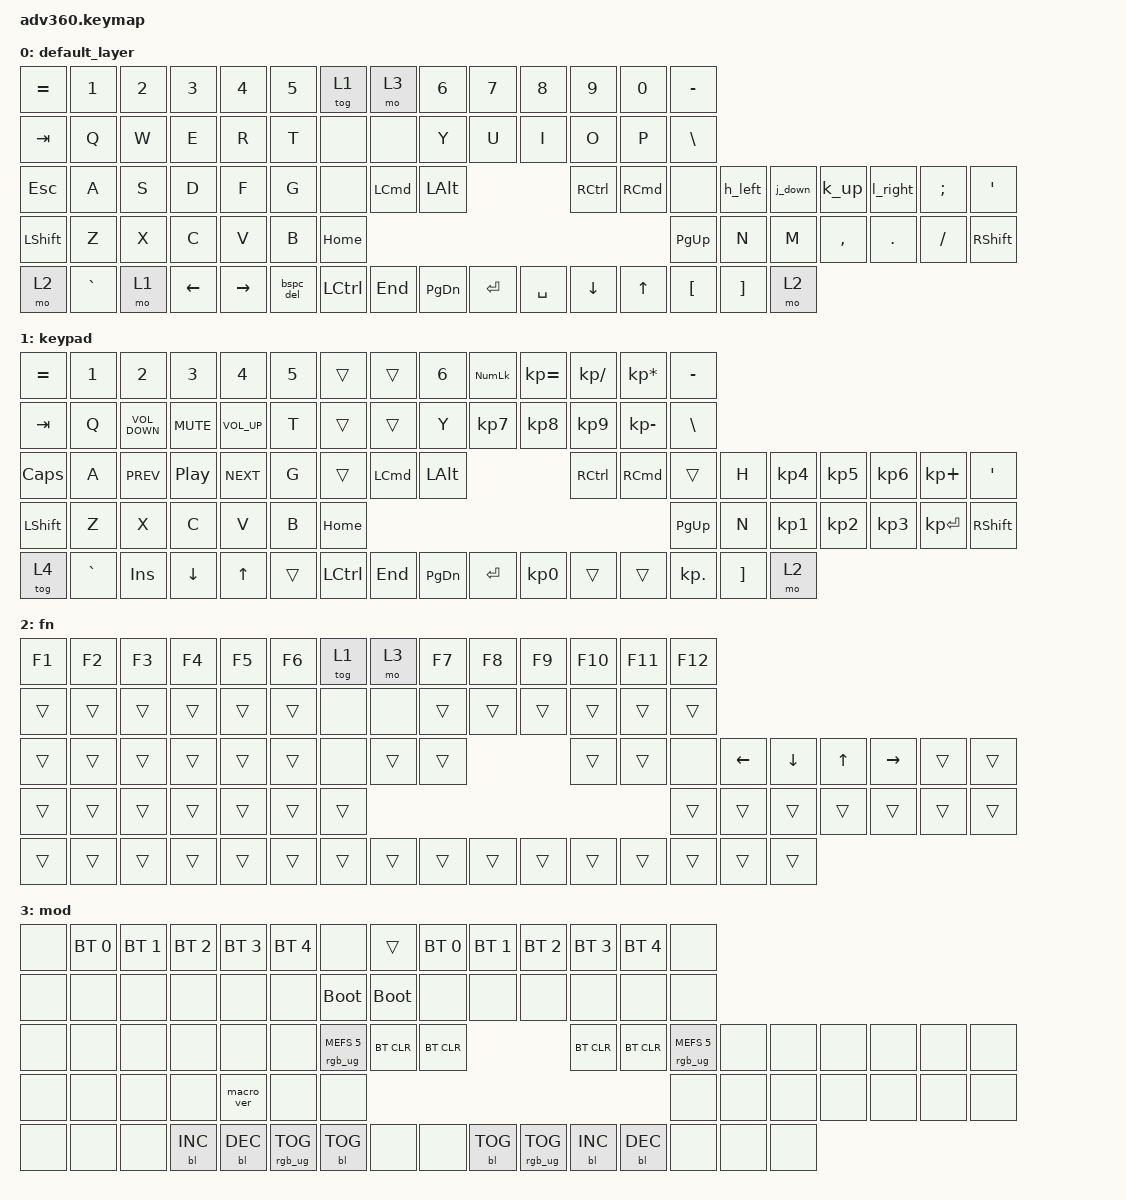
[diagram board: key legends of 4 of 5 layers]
#include <behaviors.dtsi>
#include <dt-bindings/zmk/keys.h>
#include <dt-bindings/zmk/bt.h>
#include <dt-bindings/zmk/rgb.h>
#include <dt-bindings/zmk/backlight.h>

&mt {
    tapping-term-ms = <200>;
};

/ {
    behaviors {
        #include "macros.dtsi"
        #include "version.dtsi"
        #ifndef VERSION_MACRO
        macro_ver: macro_ver {
          compatible = "zmk,behavior-macro";
          label = "macro_version";
          #binding-cells = <0>;
          bindings = <&kp RET>;
        };
        #endif

        hm: homerow_mods {
            compatible = "zmk,behavior-hold-tap";
            label = "HOMEROW_MODS";
            #binding-cells = <2>;
            tapping-term-ms = <200>;
            quick_tap_ms = <175>;
            flavor = "tap-preferred";
            bindings =
                <&kp>,
                <&kp>;
        };

        bspc_del: backspace_delete {
            compatible = "zmk,behavior-mod-morph";
            label = "SHIFT_DELETE";
            #binding-cells = <0>;
            bindings = <&kp BACKSPACE>, <&kp DELETE>;
            mods = <(MOD_LSFT|MOD_RSFT)>;
            keep-mods = <(MOD_RSFT)>;
        };

        k_up: k_up {
            compatible = "zmk,behavior-mod-morph";
            label = "K_UP";
            #binding-cells = <0>;
            bindings = <&kp K>, <&kp UP>;
            mods = <(MOD_RCTL)>;
        };

        j_down: j_down {
            compatible = "zmk,behavior-mod-morph";
            label = "J_DOWN";
            #binding-cells = <0>;
            bindings = <&kp J>, <&kp DOWN>;
            mods = <(MOD_RCTL)>;
        };

        h_left: h_left {
            compatible = "zmk,behavior-mod-morph";
            label = "H_LEFT";
            #binding-cells = <0>;
            bindings = <&kp H>, <&kp LEFT>;
            mods = <(MOD_RCTL)>;
        };

        l_right: l_right {
            compatible = "zmk,behavior-mod-morph";
            label = "L_RIGHT";
            #binding-cells = <0>;
            bindings = <&kp L>, <&kp RIGHT>;
            mods = <(MOD_RCTL)>;
        };
    };

    keymap {
        compatible = "zmk,keymap";

        default_layer {
            bindings = <
                &kp EQUAL     &kp N1  &kp N2    &kp N3     &kp N4         &kp N5            &tog 1             &mo 3     &kp N6     &kp N7     &kp N8             &kp N9             &kp N0  &kp MINUS
                  &kp TAB      &kp Q   &kp W     &kp E      &kp R          &kp T             &none             &none      &kp Y      &kp U      &kp I              &kp O              &kp P   &kp BSLH
                  &kp ESC      &kp A   &kp S     &kp D      &kp F          &kp G             &none  &kp LEFT_COMMAND   &kp LALT                        &kp RIGHT_CONTROL  &kp RIGHT_COMMAND      &none   &h_left &j_down      &k_up &l_right  &kp SEMI    &kp SQT
                &kp LSHFT      &kp Z   &kp X     &kp C      &kp V          &kp B                                       &kp HOME                                &kp PG_UP                                   &kp N   &kp M  &kp COMMA  &kp DOT  &kp FSLH  &kp RSHFT
                    &mo 2  &kp GRAVE   &mo 1  &kp LEFT  &kp RIGHT      &bspc_del  &kp LEFT_CONTROL           &kp END  &kp PG_DN  &kp ENTER  &kp SPACE           &kp DOWN             &kp UP   &kp LBKT  &kp RBKT   &mo 2
            >;
        };

        keypad {
            bindings = <
                   &kp EQUAL     &kp N1             &kp N2      &kp N3           &kp N4      &kp N5            &trans            &trans     &kp N6  &kp KP_NUM  &kp KP_EQUAL      &kp KP_DIVIDE    &kp KP_MULTIPLY   &kp MINUS
                     &kp TAB      &kp Q  &kp C_VOLUME_DOWN  &kp C_MUTE  &kp C_VOLUME_UP       &kp T            &trans            &trans      &kp Y   &kp KP_N7     &kp KP_N8          &kp KP_N9       &kp KP_MINUS    &kp BSLH
                &kp CAPSLOCK      &kp A         &kp C_PREV    &kp C_PP       &kp C_NEXT       &kp G            &trans  &kp LEFT_COMMAND   &kp LALT                            &kp RIGHT_CONTROL  &kp RIGHT_COMMAND      &trans     &kp H  &kp KP_N4  &kp KP_N5  &kp KP_N6   &kp KP_PLUS    &kp SQT
                   &kp LSHFT      &kp Z              &kp X       &kp C            &kp V       &kp B                                       &kp HOME                                    &kp PG_UP                                    &kp N  &kp KP_N1  &kp KP_N2  &kp KP_N3  &kp KP_ENTER  &kp RSHFT
                      &tog 4  &kp GRAVE         &kp INSERT    &kp DOWN           &kp UP      &trans  &kp LEFT_CONTROL           &kp END  &kp PG_DN   &kp ENTER     &kp KP_N0             &trans             &trans  &kp KP_DOT  &kp RBKT      &mo 2
            >;
        };

        fn {
            bindings = <
                &kp F1  &kp F2  &kp F3  &kp F4  &kp F5  &kp F6  &tog 1   &mo 3  &kp F7  &kp F8  &kp F9  &kp F10  &kp F11  &kp F12
                &trans  &trans  &trans  &trans  &trans  &trans   &none   &none  &trans  &trans  &trans   &trans   &trans   &trans
                &trans  &trans  &trans  &trans  &trans  &trans   &none  &trans  &trans                   &trans   &trans    &none  &kp LEFT  &kp DOWN  &kp UP  &kp RIGHT  &trans  &trans
                &trans  &trans  &trans  &trans  &trans  &trans                  &trans                   &trans                      &trans    &trans  &trans     &trans  &trans  &trans
                &trans  &trans  &trans  &trans  &trans  &trans  &trans  &trans  &trans  &trans  &trans   &trans   &trans   &trans    &trans    &trans
            >;
        };

        mod {
            bindings = <
                &none  &bt BT_SEL 0  &bt BT_SEL 1  &bt BT_SEL 2  &bt BT_SEL 3     &bt BT_SEL 4                   &none       &trans  &bt BT_SEL 0  &bt BT_SEL 1     &bt BT_SEL 2  &bt BT_SEL 3  &bt BT_SEL 4                   &none
                &none         &none         &none         &none         &none            &none             &bootloader  &bootloader         &none         &none            &none         &none         &none                   &none
                &none         &none         &none         &none         &none            &none  &rgb_ug RGB_MEFS_CMD 5   &bt BT_CLR    &bt BT_CLR                                   &bt BT_CLR    &bt BT_CLR  &rgb_ug RGB_MEFS_CMD 5   &none   &none   &none   &none   &none   &none
                &none         &none         &none         &none         &macro_ver       &none                                              &none                                        &none                                         &none   &none   &none   &none   &none   &none
                &none         &none         &none    &bl BL_INC    &bl BL_DEC  &rgb_ug RGB_TOG              &bl BL_TOG        &none         &none    &bl BL_TOG  &rgb_ug RGB_TOG    &bl BL_INC    &bl BL_DEC                   &none   &none   &none
            >;
        };

        gaming {
            bindings = <
                &trans      &trans   &trans     &trans      &trans             &trans     &trans             &trans      &trans                        &trans      &trans              &trans              &trans     &trans
                &trans      &trans   &trans     &trans      &trans             &trans     &trans             &trans      &trans                        &trans      &trans              &trans              &trans     &trans
                &trans      &trans   &trans     &trans      &trans             &trans     &trans             &trans      &trans                                                        &trans              &trans     &trans      &trans    &trans  &trans    &trans
                &trans      &trans   &trans     &trans      &trans             &trans                                    &trans                                                        &trans                                     &trans    &trans  &trans    &trans  &trans  &trans
                &trans      &trans   &trans     &trans      &trans   &kp LEFT_CONTROL  &kp SPACE             &trans      &trans                        &trans      &trans              &trans              &trans     &trans      &trans    &trans
            >;
        };
    };
};
